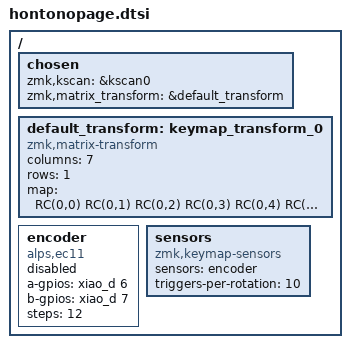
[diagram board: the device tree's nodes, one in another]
#include <dt-bindings/zmk/matrix_transform.h>

/ {
    chosen {
        zmk,kscan = &kscan0;
        zmk,matrix_transform = &default_transform;
    };

    default_transform: keymap_transform_0 {
        compatible = "zmk,matrix-transform";
        columns = <7>;
        rows = <1>;               
        map = <
            RC(0,0) RC(0,1) RC(0,2) RC(0,3) RC(0,4) RC(0,5) RC(0,6)
        >;
    };

    encoder: encoder {
        compatible = "alps,ec11";
        a-gpios = <&xiao_d 6 (GPIO_ACTIVE_HIGH | GPIO_PULL_UP)>;
        b-gpios = <&xiao_d 7 (GPIO_ACTIVE_HIGH | GPIO_PULL_UP)>;
        steps = <12>;
        status = "disabled";
    };

    sensors: sensors {
        compatible = "zmk,keymap-sensors";
        sensors = <encoder>;
        triggers-per-rotation = <10>;
    };
};
